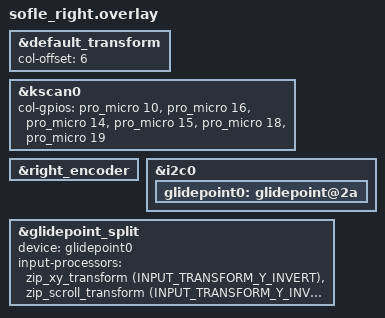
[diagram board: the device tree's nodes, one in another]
/*
 * Copyright (c) 2020 Ryan Cross
 *
 * SPDX-License-Identifier: MIT
 */

#include "sofle.dtsi"
#include "sofle_cirque.dtsi"

#include <input/processors.dtsi>
#include <dt-bindings/zmk/input_transform.h>

&default_transform {
    col-offset = <6>;
};

&kscan0 {
    col-gpios
        = <&pro_micro 10 GPIO_ACTIVE_HIGH>
        , <&pro_micro 16 GPIO_ACTIVE_HIGH>
        , <&pro_micro 14 GPIO_ACTIVE_HIGH>
        , <&pro_micro 15 GPIO_ACTIVE_HIGH>
        , <&pro_micro 18 GPIO_ACTIVE_HIGH>
        , <&pro_micro 19 GPIO_ACTIVE_HIGH>
        ;
};

&right_encoder {
    status = "okay";
};

// Cirque Trackpad
&i2c0 {
    status = "okay";   
    glidepoint0: glidepoint@2a {
        status = "okay";
    };
};

// Split peripheral input relay module peripheral. (zmk-split-peripheral-input-relay)
// / {
// 	glidepoint1: virtual_input {
// 		compatible = "zmk,virtual-input";
// 	};

//     input_relay_config_102 {
//         compatible = "zmk,split-peripheral-input-relay";
//         device = <&glidepoint0>;
// 		relay-channel = <102>;
//     };
// };

// ZMK Input Split (PR#2477)
&glidepoint_split {
    device = <&glidepoint0>;
    // Input processors that are run before event data is sent
    // to the central. Mostly useful for orientation fix ups.
    input-processors = <&zip_xy_transform (INPUT_TRANSFORM_Y_INVERT)>,
                       <&zip_scroll_transform (INPUT_TRANSFORM_Y_INVERT)>;
};
